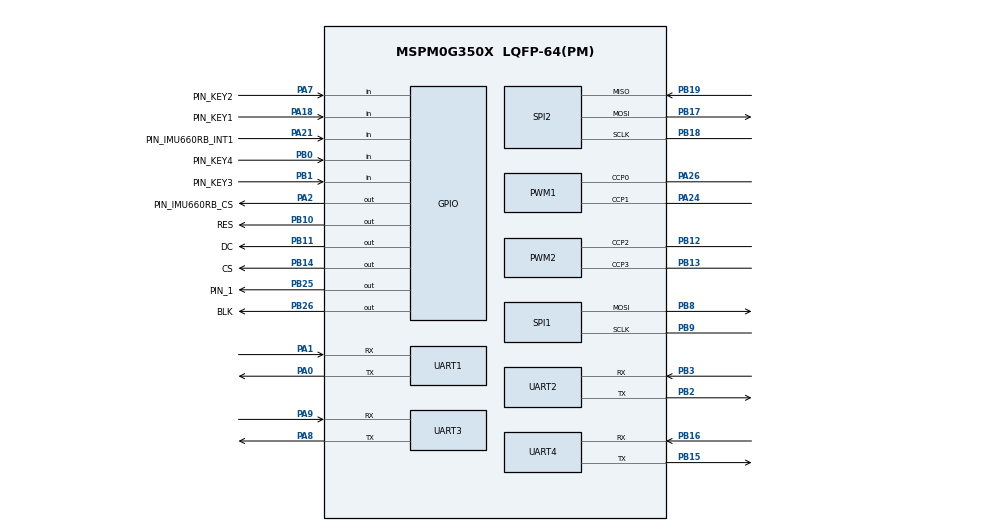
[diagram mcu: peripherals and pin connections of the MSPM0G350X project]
/**
 * @cliArgs --device "MSPM0G350X" --part "Default" --package "LQFP-64(PM)" --product "mspm0_sdk@2.02.00.05"
 * @versions {"tool":"1.21.1+3772"}
 */

/**
 * Import the modules used in this configuration.
 */
const DMA    = scripting.addModule("/ti/driverlib/DMA");
const GPIO   = scripting.addModule("/ti/driverlib/GPIO", {}, false);
const GPIO1  = GPIO.addInstance();
const GPIO2  = GPIO.addInstance();
const GPIO3  = GPIO.addInstance();
const GPIO4  = GPIO.addInstance();
const GPIO5  = GPIO.addInstance();
const GPIO6  = GPIO.addInstance();
const GPIO7  = GPIO.addInstance();
const I2C    = scripting.addModule("/ti/driverlib/I2C", {}, false);
const I2C1   = I2C.addInstance();
const PWM    = scripting.addModule("/ti/driverlib/PWM", {}, false);
const PWM1   = PWM.addInstance();
const PWM2   = PWM.addInstance();
const PWM3   = PWM.addInstance();
const SPI    = scripting.addModule("/ti/driverlib/SPI", {}, false);
const SPI1   = SPI.addInstance();
const SPI2   = SPI.addInstance();
const SYSCTL = scripting.addModule("/ti/driverlib/SYSCTL");
const TIMER  = scripting.addModule("/ti/driverlib/TIMER", {}, false);
const TIMER1 = TIMER.addInstance();
const TIMER2 = TIMER.addInstance();
const UART   = scripting.addModule("/ti/driverlib/UART", {}, false);
const UART1  = UART.addInstance();
const UART2  = UART.addInstance();
const UART3  = UART.addInstance();
const UART4  = UART.addInstance();

/**
 * Write custom configuration values to the imported modules.
 */
const divider9       = system.clockTree["UDIV"];
divider9.divideValue = 2;

const gate7  = system.clockTree["MFCLKGATE"];
gate7.enable = true;

const multiplier2         = system.clockTree["PLL_QDIV"];
multiplier2.multiplyValue = 4;

const mux4       = system.clockTree["EXHFMUX"];
mux4.inputSelect = "EXHFMUX_XTAL";

const mux8       = system.clockTree["HSCLKMUX"];
mux8.inputSelect = "HSCLKMUX_SYSPLL0";

const mux12       = system.clockTree["SYSPLLMUX"];
mux12.inputSelect = "zSYSPLLMUX_HFCLK";

const pinFunction4     = system.clockTree["HFXT"];
pinFunction4.enable    = true;
pinFunction4.inputFreq = 40;

const Board = scripting.addModule("/ti/driverlib/Board", {}, false);

GPIO1.$name                          = "SPI_LCD1";
GPIO1.associatedPins.create(4);
GPIO1.associatedPins[0].$name        = "RES";
GPIO1.associatedPins[0].assignedPort = "PORTB";
GPIO1.associatedPins[0].assignedPin  = "10";
GPIO1.associatedPins[0].pin.$assign  = "PB10";
GPIO1.associatedPins[1].$name        = "DC";
GPIO1.associatedPins[1].assignedPin  = "11";
GPIO1.associatedPins[1].assignedPort = "PORTB";
GPIO1.associatedPins[1].pin.$assign  = "PB11";
GPIO1.associatedPins[2].$name        = "CS";
GPIO1.associatedPins[2].assignedPort = "PORTB";
GPIO1.associatedPins[2].assignedPin  = "14";
GPIO1.associatedPins[2].pin.$assign  = "PB14";
GPIO1.associatedPins[3].$name        = "BLK";
GPIO1.associatedPins[3].assignedPort = "PORTB";
GPIO1.associatedPins[3].assignedPin  = "26";
GPIO1.associatedPins[3].pin.$assign  = "PB26";

GPIO2.$name                               = "GPIO_IMU660RB";
GPIO2.associatedPins.create(2);
GPIO2.associatedPins[0].$name             = "PIN_IMU660RB_CS";
GPIO2.associatedPins[0].pin.$assign       = "PA2";
GPIO2.associatedPins[1].$name             = "PIN_IMU660RB_INT1";
GPIO2.associatedPins[1].direction         = "INPUT";
GPIO2.associatedPins[1].interruptEn       = true;
GPIO2.associatedPins[1].interruptPriority = "3";
GPIO2.associatedPins[1].polarity          = "RISE";
GPIO2.associatedPins[1].pin.$assign       = "PA21";

GPIO3.$name                              = "GPIO_KEY";
GPIO3.associatedPins.create(4);
GPIO3.associatedPins[0].$name            = "PIN_KEY1";
GPIO3.associatedPins[0].direction        = "INPUT";
GPIO3.associatedPins[0].internalResistor = "PULL_UP";
GPIO3.associatedPins[0].pin.$assign      = "PA18";
GPIO3.associatedPins[1].$name            = "PIN_KEY2";
GPIO3.associatedPins[1].direction        = "INPUT";
GPIO3.associatedPins[1].internalResistor = "PULL_UP";
GPIO3.associatedPins[1].pin.$assign      = "PA7";
GPIO3.associatedPins[2].$name            = "PIN_KEY3";
GPIO3.associatedPins[2].direction        = "INPUT";
GPIO3.associatedPins[2].internalResistor = "PULL_UP";
GPIO3.associatedPins[2].pin.$assign      = "PB1";
GPIO3.associatedPins[3].$name            = "PIN_KEY4";
GPIO3.associatedPins[3].direction        = "INPUT";
GPIO3.associatedPins[3].internalResistor = "PULL_UP";
GPIO3.associatedPins[3].pin.$assign      = "PB0";

GPIO4.$name                         = "GPIO_BEEP";
GPIO4.associatedPins[0].$name       = "PIN_1";
GPIO4.associatedPins[0].pin.$assign = "PB25";

GPIO5.$name                          = "GPIO_ENCODER1";
GPIO5.associatedPins.create(2);
GPIO5.associatedPins[0].direction    = "INPUT";
GPIO5.associatedPins[0].polarity     = "RISE";
GPIO5.associatedPins[0].assignedPort = "PORTA";
GPIO5.associatedPins[0].assignedPin  = "22";
GPIO5.associatedPins[0].$name        = "PIN_B";
GPIO5.associatedPins[1].direction    = "INPUT";
GPIO5.associatedPins[1].polarity     = "RISE";
GPIO5.associatedPins[1].assignedPin  = "24";
GPIO5.associatedPins[1].assignedPort = "PORTB";
GPIO5.associatedPins[1].interruptEn  = true;
GPIO5.associatedPins[1].$name        = "PIN_A";

GPIO6.$name                          = "GPIO_ENCODER2";
GPIO6.associatedPins.create(2);
GPIO6.associatedPins[0].$name        = "PINA";
GPIO6.associatedPins[0].direction    = "INPUT";
GPIO6.associatedPins[0].assignedPort = "PORTB";
GPIO6.associatedPins[0].interruptEn  = true;
GPIO6.associatedPins[0].polarity     = "RISE";
GPIO6.associatedPins[0].assignedPin  = "4";
GPIO6.associatedPins[1].$name        = "PINB";
GPIO6.associatedPins[1].direction    = "INPUT";
GPIO6.associatedPins[1].assignedPort = "PORTB";
GPIO6.associatedPins[1].polarity     = "RISE";
GPIO6.associatedPins[1].assignedPin  = "5";

GPIO7.$name                          = "GPIO_LED";
GPIO7.associatedPins.create(2);
GPIO7.associatedPins[0].$name        = "Red";
GPIO7.associatedPins[0].assignedPort = "PORTA";
GPIO7.associatedPins[0].assignedPin  = "15";
GPIO7.associatedPins[0].initialValue = "SET";
GPIO7.associatedPins[1].$name        = "Green";
GPIO7.associatedPins[1].assignedPin  = "17";
GPIO7.associatedPins[1].assignedPort = "PORTA";
GPIO7.associatedPins[1].initialValue = "SET";

I2C1.basicEnableController             = true;
I2C1.basicControllerStandardBusSpeed   = "Fast";
I2C1.$name                             = "I2C_OLED";
I2C1.sdaPinConfig.hideOutputInversion  = scripting.forceWrite(false);
I2C1.sdaPinConfig.onlyInternalResistor = scripting.forceWrite(false);
I2C1.sdaPinConfig.passedPeripheralType = scripting.forceWrite("Digital");
I2C1.sdaPinConfig.$name                = "ti_driverlib_gpio_GPIOPinGeneric2";
I2C1.sclPinConfig.hideOutputInversion  = scripting.forceWrite(false);
I2C1.sclPinConfig.onlyInternalResistor = scripting.forceWrite(false);
I2C1.sclPinConfig.passedPeripheralType = scripting.forceWrite("Digital");
I2C1.sclPinConfig.$name                = "ti_driverlib_gpio_GPIOPinGeneric3";

PWM1.clockDivider                       = 2;
PWM1.$name                              = "PWM_A";
PWM1.timerCount                         = 4000;
PWM1.peripheral.ccp0Pin.$assign         = "PA26";
PWM1.peripheral.ccp1Pin.$assign         = "PA24";
PWM1.PWM_CHANNEL_0.$name                = "ti_driverlib_pwm_PWMTimerCC0";
PWM1.PWM_CHANNEL_1.$name                = "ti_driverlib_pwm_PWMTimerCC1";
PWM1.ccp0PinConfig.direction            = scripting.forceWrite("OUTPUT");
PWM1.ccp0PinConfig.hideOutputInversion  = scripting.forceWrite(false);
PWM1.ccp0PinConfig.onlyInternalResistor = scripting.forceWrite(false);
PWM1.ccp0PinConfig.passedPeripheralType = scripting.forceWrite("Digital");
PWM1.ccp0PinConfig.$name                = "ti_driverlib_gpio_GPIOPinGeneric14";
PWM1.ccp1PinConfig.direction            = scripting.forceWrite("OUTPUT");
PWM1.ccp1PinConfig.hideOutputInversion  = scripting.forceWrite(false);
PWM1.ccp1PinConfig.onlyInternalResistor = scripting.forceWrite(false);
PWM1.ccp1PinConfig.passedPeripheralType = scripting.forceWrite("Digital");
PWM1.ccp1PinConfig.$name                = "ti_driverlib_gpio_GPIOPinGeneric13";

PWM2.$name                      = "PWM_B";
PWM2.ccIndex                    = [2,3];
PWM2.clockDivider               = 2;
PWM2.timerCount                 = 4000;
PWM2.peripheral.ccp2Pin.$assign = "PB12";
PWM2.peripheral.ccp3Pin.$assign = "PB13";
PWM2.PWM_CHANNEL_2.$name        = "ti_driverlib_pwm_PWMTimerCC2";
PWM2.PWM_CHANNEL_3.$name        = "ti_driverlib_pwm_PWMTimerCC3";
PWM2.ccp2PinConfig.$name        = "ti_driverlib_gpio_GPIOPinGeneric16";
PWM2.ccp3PinConfig.$name        = "ti_driverlib_gpio_GPIOPinGeneric15";

PWM3.$name                              = "PWM_1";
PWM3.PWM_CHANNEL_0.$name                = "ti_driverlib_pwm_PWMTimerCC4";
PWM3.PWM_CHANNEL_1.$name                = "ti_driverlib_pwm_PWMTimerCC5";
PWM3.ccp0PinConfig.direction            = scripting.forceWrite("OUTPUT");
PWM3.ccp0PinConfig.hideOutputInversion  = scripting.forceWrite(false);
PWM3.ccp0PinConfig.onlyInternalResistor = scripting.forceWrite(false);
PWM3.ccp0PinConfig.passedPeripheralType = scripting.forceWrite("Digital");
PWM3.ccp0PinConfig.$name                = "ti_driverlib_gpio_GPIOPinGeneric17";
PWM3.ccp1PinConfig.direction            = scripting.forceWrite("OUTPUT");
PWM3.ccp1PinConfig.hideOutputInversion  = scripting.forceWrite(false);
PWM3.ccp1PinConfig.onlyInternalResistor = scripting.forceWrite(false);
PWM3.ccp1PinConfig.passedPeripheralType = scripting.forceWrite("Digital");
PWM3.ccp1PinConfig.$name                = "ti_driverlib_gpio_GPIOPinGeneric18";

SPI1.$name                              = "SPI_LCD";
SPI1.frameFormat                        = "MOTO3";
SPI1.targetBitRate                      = 20000000;
SPI1.enabledDMAEvent2Triggers           = "DL_SPI_DMA_INTERRUPT_TX";
SPI1.txFifoThreshold                    = "DL_SPI_TX_FIFO_LEVEL_ONE_FRAME";
SPI1.enabledInterrupts                  = ["DMA_DONE_TX","TX_EMPTY"];
SPI1.peripheral.$assign                 = "SPI1";
SPI1.peripheral.sclkPin.$assign         = "PB9";
SPI1.peripheral.mosiPin.$assign         = "PB8";
SPI1.sclkPinConfig.$name                = "ti_driverlib_gpio_GPIOPinGeneric8";
SPI1.sclkPinConfig.direction            = scripting.forceWrite("OUTPUT");
SPI1.sclkPinConfig.onlyInternalResistor = scripting.forceWrite(false);
SPI1.sclkPinConfig.passedPeripheralType = scripting.forceWrite("Digital");
SPI1.mosiPinConfig.$name                = "ti_driverlib_gpio_GPIOPinGeneric9";
SPI1.mosiPinConfig.direction            = scripting.forceWrite("OUTPUT");
SPI1.mosiPinConfig.hideOutputInversion  = scripting.forceWrite(false);
SPI1.mosiPinConfig.onlyInternalResistor = scripting.forceWrite(false);
SPI1.mosiPinConfig.passedPeripheralType = scripting.forceWrite("Digital");
SPI1.misoPinConfig.$name                = "ti_driverlib_gpio_GPIOPinGeneric10";
SPI1.misoPinConfig.onlyInternalResistor = scripting.forceWrite(false);
SPI1.misoPinConfig.passedPeripheralType = scripting.forceWrite("Digital");
SPI1.DMA_CHANNEL_EVENT2.$name           = "DMA_LCD_TX";
SPI1.DMA_CHANNEL_EVENT2.addressMode     = "b2f";
SPI1.DMA_CHANNEL_EVENT2.srcLength       = "BYTE";
SPI1.DMA_CHANNEL_EVENT2.dstLength       = "BYTE";

SPI2.$name                              = "SPI_IMU660RB";
SPI2.frameFormat                        = "MOTO3";
SPI2.peripheral.$assign                 = "SPI0";
SPI2.peripheral.sclkPin.$assign         = "PB18";
SPI2.peripheral.mosiPin.$assign         = "PB17";
SPI2.peripheral.misoPin.$assign         = "PB19";
SPI2.sclkPinConfig.direction            = scripting.forceWrite("OUTPUT");
SPI2.sclkPinConfig.onlyInternalResistor = scripting.forceWrite(false);
SPI2.sclkPinConfig.passedPeripheralType = scripting.forceWrite("Digital");
SPI2.sclkPinConfig.$name                = "ti_driverlib_gpio_GPIOPinGeneric6";
SPI2.mosiPinConfig.direction            = scripting.forceWrite("OUTPUT");
SPI2.mosiPinConfig.hideOutputInversion  = scripting.forceWrite(false);
SPI2.mosiPinConfig.onlyInternalResistor = scripting.forceWrite(false);
SPI2.mosiPinConfig.passedPeripheralType = scripting.forceWrite("Digital");
SPI2.mosiPinConfig.$name                = "ti_driverlib_gpio_GPIOPinGeneric7";
SPI2.misoPinConfig.onlyInternalResistor = scripting.forceWrite(false);
SPI2.misoPinConfig.passedPeripheralType = scripting.forceWrite("Digital");
SPI2.misoPinConfig.$name                = "ti_driverlib_gpio_GPIOPinGeneric12";

SYSCTL.forceDefaultClkConfig = true;
SYSCTL.clockTreeEn           = true;

TIMER1.$name              = "TIMER_0";
TIMER1.timerClkPrescale   = 4;
TIMER1.timerPeriod        = "1ms";
TIMER1.timerMode          = "PERIODIC_UP";
TIMER1.timerClkDiv        = 2;
TIMER1.interrupts         = ["ZERO"];
TIMER1.peripheral.$assign = "TIMG0";

TIMER2.$name              = "TIMER_1";
TIMER2.timerPeriod        = "10us";
TIMER2.timerMode          = "PERIODIC_UP";
TIMER2.interrupts         = ["ZERO"];
TIMER2.peripheral.$assign = "TIMG12";

UART1.$name                            = "UART0";
UART1.targetBaudRate                   = 115200;
UART1.enabledInterrupts                = ["RX"];
UART1.peripheral.rxPin.$assign         = "PA1";
UART1.peripheral.txPin.$assign         = "PA0";
UART1.txPinConfig.direction            = scripting.forceWrite("OUTPUT");
UART1.txPinConfig.hideOutputInversion  = scripting.forceWrite(false);
UART1.txPinConfig.onlyInternalResistor = scripting.forceWrite(false);
UART1.txPinConfig.passedPeripheralType = scripting.forceWrite("Digital");
UART1.txPinConfig.$name                = "ti_driverlib_gpio_GPIOPinGeneric0";
UART1.rxPinConfig.hideOutputInversion  = scripting.forceWrite(false);
UART1.rxPinConfig.onlyInternalResistor = scripting.forceWrite(false);
UART1.rxPinConfig.passedPeripheralType = scripting.forceWrite("Digital");
UART1.rxPinConfig.$name                = "ti_driverlib_gpio_GPIOPinGeneric1";

UART2.targetBaudRate                   = 115200;
UART2.$name                            = "UART3";
UART2.enabledInterrupts                = ["RX","RX_TIMEOUT_ERROR"];
UART2.uartClkSrc                       = "MFCLK";
UART2.peripheral.$assign               = "UART3";
UART2.peripheral.rxPin.$assign         = "PB3";
UART2.peripheral.txPin.$assign         = "PB2";
UART2.txPinConfig.direction            = scripting.forceWrite("OUTPUT");
UART2.txPinConfig.hideOutputInversion  = scripting.forceWrite(false);
UART2.txPinConfig.onlyInternalResistor = scripting.forceWrite(false);
UART2.txPinConfig.passedPeripheralType = scripting.forceWrite("Digital");
UART2.txPinConfig.$name                = "ti_driverlib_gpio_GPIOPinGeneric4";
UART2.rxPinConfig.hideOutputInversion  = scripting.forceWrite(false);
UART2.rxPinConfig.onlyInternalResistor = scripting.forceWrite(false);
UART2.rxPinConfig.passedPeripheralType = scripting.forceWrite("Digital");
UART2.rxPinConfig.$name                = "ti_driverlib_gpio_GPIOPinGeneric5";

UART3.$name                            = "UART1";
UART3.targetBaudRate                   = 115200;
UART3.enabledInterrupts                = ["RX"];
UART3.peripheral.$assign               = "UART1";
UART3.peripheral.rxPin.$assign         = "PA9";
UART3.peripheral.txPin.$assign         = "PA8";
UART3.txPinConfig.direction            = scripting.forceWrite("OUTPUT");
UART3.txPinConfig.hideOutputInversion  = scripting.forceWrite(false);
UART3.txPinConfig.onlyInternalResistor = scripting.forceWrite(false);
UART3.txPinConfig.passedPeripheralType = scripting.forceWrite("Digital");
UART3.txPinConfig.$name                = "ti_driverlib_gpio_GPIOPinGeneric11";
UART3.rxPinConfig.hideOutputInversion  = scripting.forceWrite(false);
UART3.rxPinConfig.onlyInternalResistor = scripting.forceWrite(false);
UART3.rxPinConfig.passedPeripheralType = scripting.forceWrite("Digital");
UART3.rxPinConfig.$name                = "ti_driverlib_gpio_GPIOPinGeneric19";

UART4.targetBaudRate                   = 115200;
UART4.enabledInterrupts                = ["RX"];
UART4.$name                            = "UART2";
UART4.peripheral.rxPin.$assign         = "PB16";
UART4.peripheral.txPin.$assign         = "PB15";
UART4.txPinConfig.direction            = scripting.forceWrite("OUTPUT");
UART4.txPinConfig.hideOutputInversion  = scripting.forceWrite(false);
UART4.txPinConfig.onlyInternalResistor = scripting.forceWrite(false);
UART4.txPinConfig.passedPeripheralType = scripting.forceWrite("Digital");
UART4.txPinConfig.$name                = "ti_driverlib_gpio_GPIOPinGeneric0_COPY";
UART4.rxPinConfig.hideOutputInversion  = scripting.forceWrite(false);
UART4.rxPinConfig.onlyInternalResistor = scripting.forceWrite(false);
UART4.rxPinConfig.passedPeripheralType = scripting.forceWrite("Digital");
UART4.rxPinConfig.$name                = "ti_driverlib_gpio_GPIOPinGeneric1_COPY";

/**
 * Pinmux solution for unlocked pins/peripherals. This ensures that minor changes to the automatic solver in a future
 * version of the tool will not impact the pinmux you originally saw.  These lines can be completely deleted in order to
 * re-solve from scratch.
 */
pinFunction4.peripheral.$suggestSolution            = "SYSCTL";
pinFunction4.peripheral.hfxInPin.$suggestSolution   = "PA5";
pinFunction4.peripheral.hfxOutPin.$suggestSolution  = "PA6";
Board.peripheral.$suggestSolution                   = "DEBUGSS";
Board.peripheral.swclkPin.$suggestSolution          = "PA20";
Board.peripheral.swdioPin.$suggestSolution          = "PA19";
GPIO5.associatedPins[0].pin.$suggestSolution        = "PA22";
GPIO5.associatedPins[1].pin.$suggestSolution        = "PB24";
GPIO6.associatedPins[0].pin.$suggestSolution        = "PB4";
GPIO6.associatedPins[1].pin.$suggestSolution        = "PB5";
GPIO7.associatedPins[0].pin.$suggestSolution        = "PA15";
GPIO7.associatedPins[1].pin.$suggestSolution        = "PA17";
I2C1.peripheral.$suggestSolution                    = "I2C0";
I2C1.peripheral.sdaPin.$suggestSolution             = "PA28";
I2C1.peripheral.sclPin.$suggestSolution             = "PA31";
PWM1.peripheral.$suggestSolution                    = "TIMG7";
PWM2.peripheral.$suggestSolution                    = "TIMA0";
PWM3.peripheral.$suggestSolution                    = "TIMA1";
PWM3.peripheral.ccp0Pin.$suggestSolution            = "PA10";
PWM3.peripheral.ccp1Pin.$suggestSolution            = "PA11";
SPI1.peripheral.misoPin.$suggestSolution            = "PA16";
SPI1.DMA_CHANNEL_EVENT2.peripheral.$suggestSolution = "DMA_CH0";
UART1.peripheral.$suggestSolution                   = "UART0";
UART4.peripheral.$suggestSolution                   = "UART2";
